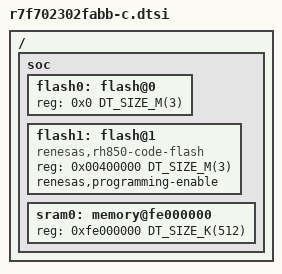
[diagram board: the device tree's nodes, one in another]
/*
 * Copyright (c) 2026 Renesas Electronics Corporation
 *
 * SPDX-License-Identifier: Apache-2.0
 */

#include <rh850/renesas/rh850u2a/r7f702302.dtsi>

/ {
	soc {
		flash0: flash@0 {
			reg = <0x0 DT_SIZE_M(3)>;
		};

		flash1: flash@1 {
			compatible = "renesas,rh850-code-flash";
			reg = <0x00400000 DT_SIZE_M(3)>;
			renesas,programming-enable;
		};

		sram0: memory@fe000000 {
			reg = <0xfe000000 DT_SIZE_K(512)>;
		};
	};
};
